AUTOSAR XML (schema 4.0)
package /VehicleSystem
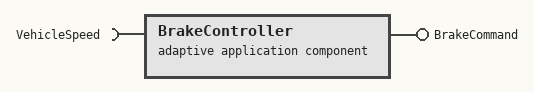
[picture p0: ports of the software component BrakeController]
  adaptive application sw component type BrakeController
    provide port BrakeCommand
    require port VehicleSpeed
